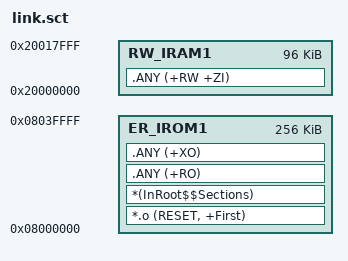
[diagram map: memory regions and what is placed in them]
; *************************************************************
; *** Scatter-Loading Description File generated by uVision ***
; *************************************************************

LR_IROM1 0x08000000 0x00040000  {    ; 256KB Flash (0x40000 = 256KB)
  ER_IROM1 0x08000000 0x00040000  {
   *.o (RESET, +First)
   *(InRoot$$Sections)
   .ANY (+RO)
   .ANY (+XO)
  }
  RW_IRAM1 0x20000000 0x00018000  {  ; 96KB RAM (0x18000 = 96KB)
   .ANY (+RW +ZI)
  }
}

